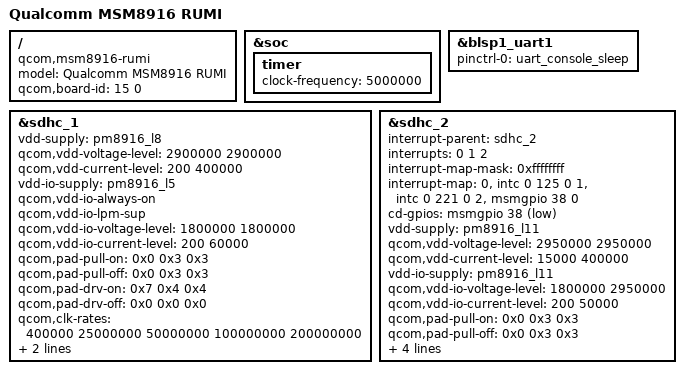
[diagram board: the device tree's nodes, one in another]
/* Copyright (c) 2013, The Linux Foundation. All rights reserved.
 *
 * This program is free software; you can redistribute it and/or modify
 * it under the terms of the GNU General Public License version 2 and
 * only version 2 as published by the Free Software Foundation.
 *
 * This program is distributed in the hope that it will be useful,
 * but WITHOUT ANY WARRANTY; without even the implied warranty of
 * MERCHANTABILITY or FITNESS FOR A PARTICULAR PURPOSE.  See the
 * GNU General Public License for more details.
 */

/dts-v1/;

/include/ "msm8916.dtsi"
/include/ "msm8916-pinctrl.dtsi"

/ {
	model = "Qualcomm MSM8916 RUMI";
	compatible = "qcom,msm8916-rumi", "qcom,msm8916", "qcom,rumi";
	qcom,board-id= <15 0>;
};

&soc {
	timer {
		clock-frequency = <5000000>;
	};
};

&blsp1_uart1 {
	status = "ok";
	pinctrl-names = "default";
	pinctrl-0 = <&uart_console_sleep>;
};

&sdhc_1 {
	vdd-supply = <&pm8916_l8>;
	qcom,vdd-voltage-level = <2900000 2900000>;
	qcom,vdd-current-level = <200 400000>;

	vdd-io-supply = <&pm8916_l5>;
	qcom,vdd-io-always-on;
	qcom,vdd-io-lpm-sup;
	qcom,vdd-io-voltage-level = <1800000 1800000>;
	qcom,vdd-io-current-level = <200 60000>;

	qcom,pad-pull-on = <0x0 0x3 0x3>; /* no-pull, pull-up, pull-up */
	qcom,pad-pull-off = <0x0 0x3 0x3>; /* no-pull, pull-up, pull-up */
	qcom,pad-drv-on = <0x7 0x4 0x4>; /* 16mA, 10mA, 10mA */
	qcom,pad-drv-off = <0x0 0x0 0x0>; /* 2mA, 2mA, 2mA */

	qcom,clk-rates = <400000 25000000 50000000 100000000 200000000>;
	qcom,bus-speed-mode = "HS200_1p8v", "DDR_1p8v";
	qcom,nonremovable;

	status = "ok";
};

&sdhc_2 {
	 #address-cells = <0>;
	interrupt-parent = <&sdhc_2>;
	interrupts = <0 1 2>;
	#interrupt-cells = <1>;
	interrupt-map-mask = <0xffffffff>;
	interrupt-map = <0 &intc 0 125 0
			1 &intc 0 221 0
			2 &msmgpio 38 0>;
	interrupt-names = "hc_irq", "pwr_irq", "status_irq";
	cd-gpios = <&msmgpio 38 0x1>;

	vdd-supply = <&pm8916_l11>;
	qcom,vdd-voltage-level = <2950000 2950000>;
	qcom,vdd-current-level = <15000 400000>;

	vdd-io-supply = <&pm8916_l11>;
	qcom,vdd-io-voltage-level = <1800000 2950000>;
	qcom,vdd-io-current-level = <200 50000>;

	qcom,pad-pull-on = <0x0 0x3 0x3>; /* no-pull, pull-up, pull-up */
	qcom,pad-pull-off = <0x0 0x3 0x3>; /* no-pull, pull-up, pull-up */
	qcom,pad-drv-on = <0x7 0x4 0x4>; /* 16mA, 10mA, 10mA */
	qcom,pad-drv-off = <0x0 0x0 0x0>; /* 2mA, 2mA, 2mA */

	qcom,clk-rates = <400000 25000000 50000000 100000000 200000000>;

	status = "ok";
};
